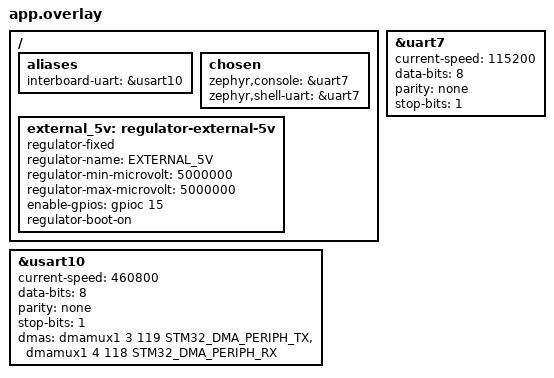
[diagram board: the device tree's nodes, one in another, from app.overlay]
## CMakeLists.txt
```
cmake_minimum_required(VERSION 3.20.0)
set(INSTALLED_CONFIG ${CMAKE_CURRENT_LIST_DIR}/../../config/vehicle/installed)
set(CONF_FILE ${INSTALLED_CONFIG}/base.conf ${INSTALLED_CONFIG}/gimbal.conf ${CMAKE_CURRENT_LIST_DIR}/prj.conf)
find_package(Zephyr REQUIRED HINTS $ENV{ZEPHYR_BASE})
project(sentry_gimbal)
target_sources(app PRIVATE src/main.cpp)
```

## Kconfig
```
mainmenu "SkyWalker sentry gimbal"
source "Kconfig.zephyr"
```

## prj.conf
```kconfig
# Installed manual/navigation/auto-aim application.
# Enable the status LED only in apps which actually use it.
CONFIG_SKYWALKER_STATUS_LED=y
CONFIG_SKYWALKER_DRIVER_MOTOR=y
CONFIG_SKYWALKER_MOTOR_DJI=y
CONFIG_SKYWALKER_MOTOR_DM=y
CONFIG_SKYWALKER_LIB_CONTROL=y
CONFIG_SKYWALKER_LIB_MOTOR_CONTROL=y
CONFIG_SKYWALKER_LIB_COMMUNICATION=y
CONFIG_SKYWALKER_UART_TRANSPORT=y
CONFIG_SKYWALKER_INTERBOARD_ENDPOINT=y
CONFIG_SKYWALKER_LIB_ROBOTICS=y
CONFIG_SKYWALKER_REMOTE_DR16=y
CONFIG_SKYWALKER_REMOTE_RECEIVER=y
CONFIG_SKYWALKER_NAVIGATION_RECEIVER=y
CONFIG_SKYWALKER_REFEREE=y
CONFIG_SKYWALKER_ROBOTICS_COMMAND=y
CONFIG_SKYWALKER_COMMAND_SERVICE=y
CONFIG_SKYWALKER_ROBOTICS_GIMBAL=y
CONFIG_SKYWALKER_ROBOTICS_INERTIAL_GIMBAL=y
CONFIG_SKYWALKER_ROBOTICS_BIG_YAW=y
# 摩擦轮/拨盘执行器与 GM6020 小 Yaw 共用 CAN1；命令由仲裁器 ShooterCommand 给出。
CONFIG_SKYWALKER_ROBOTICS_SHOOTER=y
CONFIG_SKYWALKER_IMU_RECEIVER=y
# 视觉链路：USB CDC ACM（板载 usbotg_hs，PA11/PA12），AB 协议在云台板内解析。
# 本应用在左 Middle 导航档同时启用视觉自瞄，左 Up 保留手动。
CONFIG_USB_DEVICE_STACK_NEXT=y
CONFIG_CDC_ACM_SERIAL_INITIALIZE_AT_BOOT=y
CONFIG_CDC_ACM_SERIAL_PRODUCT_STRING="SkyWalker Vision"
CONFIG_SKYWALKER_VISION=y
CONFIG_SKYWALKER_VISION_AB=y
CONFIG_SKYWALKER_VISION_RECEIVER=y
# 板载 BMI088 测量大 Yaw 载体；CAN3 外置头部 IMU 用于视觉回传及自瞄世界参考。
CONFIG_SENSOR=y
CONFIG_BMI08X=y
CONFIG_SKYWALKER_IMU_BMI088=y
CONFIG_SKYWALKER_ATTITUDE_EKF=y
```

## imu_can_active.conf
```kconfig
CONFIG_VEHICLE_ENCODER_ONLY=n
CONFIG_SKYWALKER_IMU_DM_CAN=y
CONFIG_SKYWALKER_IMU_DM_CAN_PASSIVE=n
```

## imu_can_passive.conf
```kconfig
# Set the module to passive/request mode using the vendor tool as well.
CONFIG_SKYWALKER_IMU_DM_CAN=y
CONFIG_VEHICLE_ENCODER_ONLY=n
CONFIG_SKYWALKER_IMU_DM_CAN_PASSIVE=y
```

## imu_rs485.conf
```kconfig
CONFIG_SKYWALKER_IMU_DM_CAN=n
CONFIG_VEHICLE_ENCODER_ONLY=n
CONFIG_SKYWALKER_IMU_DM_RS485=y
```

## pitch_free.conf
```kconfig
CONFIG_VEHICLE_LOCK_PITCH=n
```

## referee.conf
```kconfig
CONFIG_VEHICLE_REFEREE=y
```

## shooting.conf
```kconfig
CONFIG_VEHICLE_REFEREE=y
CONFIG_VEHICLE_VISION_EXECUTE=y
CONFIG_VEHICLE_ENCODER_ONLY=n
CONFIG_VEHICLE_SHOOTING=y
CONFIG_VEHICLE_LOCK_PITCH=n
```

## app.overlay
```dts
#include "../../samples/robotics/common/vehicle_mc02.overlay"

/* USART10 interboard link, UART7 diagnostic console. */
/ {
    aliases {
        interboard-uart = &usart10;
        /delete-property/ telemetry-uart;
    };

    chosen {
        zephyr,console = &uart7;
        zephyr,shell-uart = &uart7;
    };

    // MC02 Power_5V_EN: shared external 5 V rail, including CAN3 connector power.
    external_5v: regulator-external-5v {
        compatible = "regulator-fixed";
        regulator-name = "EXTERNAL_5V";
        regulator-min-microvolt = <5000000>;
        regulator-max-microvolt = <5000000>;
        enable-gpios = <&gpioc 15 GPIO_ACTIVE_HIGH>;
        regulator-boot-on;
    };
};

&usart10 {
    status = "okay";
    current-speed = <460800>;
    data-bits = <8>;
    parity = "none";
    stop-bits = "1";
    dmas = <&dmamux1 3 119 STM32_DMA_PERIPH_TX>,
           <&dmamux1 4 118 STM32_DMA_PERIPH_RX>;
    dma-names = "tx", "rx";
};

/* UART7 is reserved for logs; remap vision-uart before enabling vision. */
&uart7 {
    status = "okay";
    current-speed = <115200>;
    data-bits = <8>;
    parity = "none";
    stop-bits = "1";
    /delete-property/ dmas;
    /delete-property/ dma-names;
};
```

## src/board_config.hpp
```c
// TODO(legacy): historical private implementation. The active entry now uses
// samples/robotics/common/vehicle_bench.hpp and central vehicle calibration.
#pragma once
#include <zephyr/device.h>
#include <zephyr/devicetree.h>
#include <control/position_motor.hpp>
#include <drivers/motor/can_bus.hpp>
#include <drivers/motor/dji_motor.hpp>
#include <drivers/motor/dm_motor.hpp>
#include <robotics/gimbal/gimbal_axis.hpp>
#include <robotics/command/command_arbiter.hpp>
#include <communication/referee/referee_protocol.hpp>
#include <communication/interboard/configured_interboard_transport.hpp>
namespace board_config {
// Edit this application only; samples and the chassis app have their own configuration.
inline constexpr bool connections_configured = false;
inline constexpr bool require_referee_for_motion = true;
inline constexpr auto referee_version = skywalker::communication::RefereeVersion::Unspecified;
inline constexpr std::uint32_t permission_timeout_ms = 300, command_timeout_ms = 100,
                               chassis_heartbeat_timeout_ms = 100, chassis_feedback_timeout_ms = 100;
inline const skywalker::robotics::CommandArbiter::Config command_policy = [] {
    skywalker::robotics::CommandArbiter::Config c{};
    c.require_referee_for_motion = require_referee_for_motion;
    c.permission_timeout_ms = permission_timeout_ms;
    c.input_timeout_ms = command_timeout_ms;
    c.allow_auto = false; // No vision receiver is assembled in this application.
    return c;
}();
#if DT_NODE_HAS_STATUS(DT_ALIAS(interboard_uart), okay)
inline const device *interboard_uart = DEVICE_DT_GET(DT_ALIAS(interboard_uart));
#else
inline const device *interboard_uart = nullptr;
#endif
// Change only kind to select the physical link; both boards must agree.
inline const skywalker::communication::ConfiguredInterBoardTransport::Config interboard_transport = [] {
    using namespace skywalker::communication;
    ConfiguredInterBoardTransport::Config c{};
    c.kind = InterBoardTransportKind::Uart;
    c.uart = interboard_uart;
#if DT_NODE_HAS_STATUS(DT_ALIAS(interboard_rs485), okay)
    c.rs485.uart = DEVICE_DT_GET(DT_ALIAS(interboard_rs485));
#endif
    c.rs485.role = Rs485InterBoardTransport::Role::Coordinator;
#if DT_NODE_HAS_STATUS(DT_ALIAS(interboard_can), okay)
    c.can.can = DEVICE_DT_GET(DT_ALIAS(interboard_can));
#endif
    c.can.tx_id = 0x600;
    c.can.rx_id = 0x601;
    return c;
}();
#if DT_NODE_HAS_STATUS(DT_ALIAS(remote_uart), okay)
inline const device *remote_uart = DEVICE_DT_GET(DT_ALIAS(remote_uart));
#else
inline const device *remote_uart = nullptr;
#endif
#if DT_NODE_HAS_STATUS(DT_ALIAS(referee_uart), okay)
inline const device *referee_uart = DEVICE_DT_GET(DT_ALIAS(referee_uart));
#else
inline const device *referee_uart = nullptr;
#endif
#if DT_NODE_HAS_STATUS(DT_NODELABEL(can1), okay)
inline const device *yaw_can = DEVICE_DT_GET(DT_NODELABEL(can1));
#else
inline const device *yaw_can = nullptr;
#endif
// This one factory is the active yaw configuration. Confirm the physical CAN ID,
// zero and current control mode before setting connections_configured to true.
inline auto yawMotorConfig() {
    return skywalker::motor::dji::gm6020({
        .id = 1,
        .current_limit_a = 1.5f,
        .encoder_zero_ticks = 0,
        .current_mode_confirmed = false,
        .timing = {20, 20, 30, 100},
    });
    // For a DM J4310 MIT yaw, replace the return above with:
    // return skywalker::motor::dm::j4310Mit({.id = <motor ID>,
    //     .master_id = <feedback CAN ID>, .position_max_rad = <drive range>,
    //     .velocity_max_rad_s = <drive range>, .torque_max_nm = <drive range>,
    //     .torque_limit_nm = <application limit>, .timing = {50, 20, 50, 3000}});
    // Also select a mechanically valid Limited yaw topology below: DM currently
    // does not provide the fixed-zero absolute angle required by Continuous yaw.
    // Recheck the PID gains and effort cap in NewtonMeter before enabling motion.
}

inline constexpr skywalker::robotics::GimbalAxisConfig yaw{skywalker::robotics::AxisTopology::Continuous, -3.14159265f,
                                                           3.14159265f, 1.0f, true};
inline skywalker::control::PositionMotor::Config motorConfig(const skywalker::motor::MotorInfo &info) {
    skywalker::control::PositionMotor::Config c{};
    if ((info.capabilities & skywalker::motor::CommandCurrent) != 0u)
        c.effort_unit = skywalker::control::EffortUnit::Ampere;
    else if ((info.capabilities & skywalker::motor::CommandTorque) != 0u)
        c.effort_unit = skywalker::control::EffortUnit::NewtonMeter;
    c.safety = {12, 0};
    c.reference = yaw.topology == skywalker::robotics::AxisTopology::Continuous
                      ? skywalker::control::PositionReference::AbsoluteNearest
                      : skywalker::control::PositionReference::DriverContinuous;
    c.loop.position = {3, 0, 0, 0, -3, 3, -6, 6, 0.01f, 0.001f, 0.02f};
    c.loop.velocity.regulator.feedback = {0.03f, 0.1f, 0, 0, -0.3f, 0.3f, -0.3f, 0.3f, 0, 0.001f, 0.02f};
    c.loop.velocity.reference_slew = {10, 10};
    c.loop.velocity.requested_velocity_abs_max_rad_s = 6;
    c.loop.velocity.effort_abs_max = 0.3f;
    return c;
}
} // namespace board_config
```

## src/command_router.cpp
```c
#include "command_router.hpp"
RouteReport CommandRouter::route(const skywalker::robotics::RobotCommand &command) {
    const int result = local_.put(command.gimbal);
    remote_.submit(command.chassis);
    return {result};
}
```

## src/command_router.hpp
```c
#pragma once
#include <latest.hpp>
#include <communication/interboard/interboard_endpoint.hpp>
struct RouteReport { int local_gimbal_result = 0; };
class CommandRouter {
public:
    CommandRouter(Latest<skywalker::robotics::GimbalCommand> &local,
                  skywalker::communication::InterBoardEndpoint &remote) : local_(local), remote_(remote) {}
    RouteReport route(const skywalker::robotics::RobotCommand &);
private:
    Latest<skywalker::robotics::GimbalCommand> &local_;
    skywalker::communication::InterBoardEndpoint &remote_;
};
```

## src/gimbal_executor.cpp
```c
#include "gimbal_executor.hpp"
#include <cerrno>
#include <cmath>
using namespace skywalker;
using namespace skywalker::robotics;
namespace {
bool permanent(int error) {
    return error == -EINVAL || error == -ENOTSUP || error == -ENODEV || error == -ERANGE ||
           error == -EBUSY || error == -ENOSPC;
}
}
RunStatus GimbalExecutor::begin() {
    if (checked_) return status_;
    return update({}, core::monotonicTimeUs());
}
void GimbalExecutor::suspend() {
    const auto state = drive_.snapshot().state;
    if (state == motor::MotorState::Active || state == motor::MotorState::Enabling)
        (void)drive_.disable();
}
RunStatus GimbalExecutor::update(const GimbalCommand &command, core::TimeUs now_us) {
    const auto now = now_us / 1000;
    const bool cycle_valid = have_time_ && now_us > previous_us_ && now_us - previous_us_ <= 20000;
    const float dt = cycle_valid ? float(now_us - previous_us_) / 1000000.0f : 0;
    previous_us_ = now_us;
    have_time_ = true;
    status_.ready = false;
    const auto finish = [&](RunState state, WaitReason reason, int error = 0) {
        status_.state = state;
        status_.reason = reason;
        status_.error = error;
        status_.generation = static_cast<std::uint32_t>(drive_.snapshot().enable_generation);
        status_.stamp = {now, status_.stamp.sequence + 1, true};
        return status_;
    };
    const bool requested = command.mode != GimbalMode::Disabled &&
                           isFresh(command.stamp, now, board_config::command_timeout_ms);
    if (!requested) suspend(); // Never wait for a retry deadline to withdraw output.
    if (!checked_) {
        checked_ = true;
        config_error_ = board_config::connections_configured ? axis_.validate() : -ENODEV;
    }
    if (config_error_ < 0) return finish(RunState::Blocked, WaitReason::Configuration, config_error_);
    if (!configured_) {
        if (now < retry_ms_) return finish(RunState::Recovering, WaitReason::Transport, -EAGAIN);
        int ret = 0;
        if (!attached_) { ret = bus_.attach(drive_); attached_ = ret == 0; }
        if (ret == 0 && !started_) { ret = bus_.start(); started_ = ret == 0; }
        if (ret == 0) { ret = axis_.begin(); configured_ = ret == 0; }
        if (ret < 0) {
            retry_ms_ = now + 100;
            if (permanent(ret)) config_error_ = ret;
            return finish(config_error_ < 0 ? RunState::Blocked : RunState::Recovering, WaitReason::Configuration, ret);
        }
    }
    auto view = drive_.snapshot();
    if (view.state == motor::MotorState::Fault) {
        const auto reason = view.last_fault.reason;
        const bool transient = reason == motor::FaultReason::UnexpectedDisabled || reason == motor::FaultReason::EnableTimeout;
        if (!transient) return finish(RunState::Blocked, WaitReason::Drive, view.last_fault.error);
        if (view.feedback_fresh && now >= retry_ms_) {
            retry_ms_ = now + 100;
            const int ret = drive_.clearFault();
            if (ret < 0 && ret != -EAGAIN && ret != -EBUSY)
                return finish(RunState::Recovering, WaitReason::Drive, ret);
        }
        return finish(RunState::Recovering, WaitReason::Drive, view.last_fault.error);
    }
    const auto axis_status = axis_.poll(now);
    const bool active = drive_.active();
    status_.ready = axis_status.ready_for_enable || active || view.state == motor::MotorState::Enabling;
    if (!requested) return finish(RunState::Disabled, WaitReason::Command);
    if (command.mode > GimbalMode::AbsoluteAngle || !std::isfinite(command.yaw_target_rad) ||
        !std::isfinite(command.yaw_rate_rad_s)) {
        suspend();
        return finish(RunState::Blocked, WaitReason::Command, -EINVAL);
    }
    if (!axis_status.feedback_healthy) {
        suspend();
        status_.ready = false;
        return finish(RunState::Recovering, WaitReason::Feedback, axis_status.error);
    }
    if (active) {
        if (!cycle_valid) {
            suspend();
            status_.ready = false;
            return finish(RunState::Recovering, WaitReason::Cycle, -ESTALE);
        }
        int ret = axis_.update({command.mode, command.yaw_target_rad, command.yaw_rate_rad_s}, SafetyAction::Active, dt);
        if (ret == 0) ret = bus_.commit().error;
        if (ret < 0) {
            suspend();
            status_.ready = false;
            return finish(RunState::Recovering, WaitReason::Drive, ret);
        }
        status_.last_command_sequence = command.stamp.sequence;
        return finish(RunState::Active, WaitReason::None);
    }
    if (view.state == motor::MotorState::Enabling)
        return finish(RunState::Recovering, WaitReason::Drive);
    // The command must have been produced after this preparation boundary.
    if (!axis_status.ready_for_enable)
        return finish(RunState::Recovering, WaitReason::Reference, axis_status.error);
    if (command.stamp.timestamp_ms <= axis_status.ready_since_ms)
        return finish(RunState::Recovering, WaitReason::Command, -EAGAIN);
    if (now < retry_ms_) return finish(RunState::Recovering, WaitReason::Drive, -EAGAIN);
    int ret = axis_.reset();
    if (ret == 0) ret = drive_.enable();
    retry_ms_ = now + 100;
    return finish(RunState::Recovering, ret < 0 ? WaitReason::Reference : WaitReason::Drive, ret);
}
```

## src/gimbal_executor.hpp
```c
// TODO(legacy): historical private implementation. The active entry now uses
// samples/robotics/common/vehicle_bench.hpp and central vehicle calibration.
#pragma once
#include <core/clock.hpp>
#include <robotics/execution/run_status.hpp>
#include "board_config.hpp"
// Single execution-thread owner; this object owns the CAN controller and axis.
class GimbalExecutor {
public:
    skywalker::robotics::RunStatus begin();
    skywalker::robotics::RunStatus update(const skywalker::robotics::GimbalCommand &, skywalker::core::TimeUs now_us);
private:
    void suspend();
    skywalker::motor::CanBus bus_{board_config::yaw_can};
    skywalker::motor::Motor drive_{board_config::yawMotorConfig()};
    skywalker::robotics::GimbalAxis axis_{drive_, board_config::motorConfig(drive_.info()), board_config::yaw};
    skywalker::robotics::RunStatus status_{};
    bool checked_ = false, attached_ = false, started_ = false, configured_ = false, have_time_ = false;
    int config_error_ = 0;
    skywalker::core::TimeUs previous_us_ = 0;
    std::uint64_t retry_ms_ = 0;
};
```

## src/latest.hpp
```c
#pragma once
#include <cerrno>
#include <zephyr/kernel.h>
// Application-owned coherent snapshots; no I/O or callbacks while holding the lock.
template<class T> class Latest {
public:
    Latest() { k_mutex_init(&mutex_); }
    int put(const T &value) { if (k_mutex_lock(&mutex_,K_NO_WAIT)<0) return -EAGAIN; value_=value; k_mutex_unlock(&mutex_); return 0; }
    int get(T &value) { if (k_mutex_lock(&mutex_,K_NO_WAIT)<0) return -EAGAIN; value=value_; k_mutex_unlock(&mutex_); return 0; }
private: k_mutex mutex_{}; T value_{};
};
```
